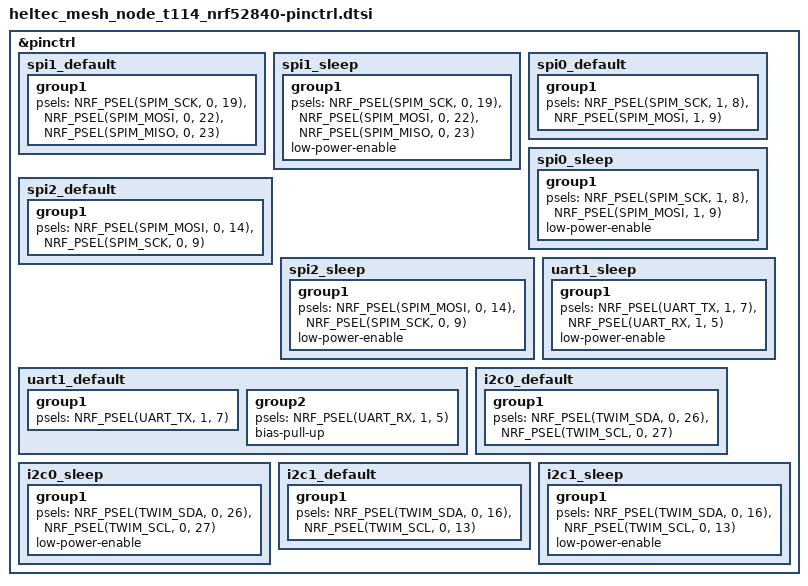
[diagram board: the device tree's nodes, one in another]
/*
 * Copyright (c) 2026 Bruce Fitzsimons
 * SPDX-License-Identifier: Apache-2.0
 *
 * Pin assignments verified against:
 *   - Heltec MeshNode T114 V2.1 schematic
 *     (https://resource.heltec.cn/download/Mesh_Node_T114/schematic/MeshNode-T114_V2.1.pdf)
 *   - Meshtastic firmware variant.h
 *     (variants/nrf52840/heltec_mesh_node_t114/variant.h)
 *
 * SPI bus assignment (Zephyr instance numbering, distinct from Arduino's):
 *   spi0 -> ST7789V TFT display
 *   spi1 -> SX1262 LoRa radio
 *   spi2 -> WS2812 / SK6812 NeoPixel (dummy SCK)
 */

&pinctrl {
	/* SX1262 LoRa radio */
	spi1_default: spi1_default {
		group1 {
			psels = <NRF_PSEL(SPIM_SCK, 0, 19)>,
				<NRF_PSEL(SPIM_MOSI, 0, 22)>,
				<NRF_PSEL(SPIM_MISO, 0, 23)>;
		};
	};

	spi1_sleep: spi1_sleep {
		group1 {
			psels = <NRF_PSEL(SPIM_SCK, 0, 19)>,
				<NRF_PSEL(SPIM_MOSI, 0, 22)>,
				<NRF_PSEL(SPIM_MISO, 0, 23)>;
			low-power-enable;
		};
	};

	/* ST7789V display — write-only, no MISO line */
	spi0_default: spi0_default {
		group1 {
			psels = <NRF_PSEL(SPIM_SCK, 1, 8)>,
				<NRF_PSEL(SPIM_MOSI, 1, 9)>;
		};
	};

	spi0_sleep: spi0_sleep {
		group1 {
			psels = <NRF_PSEL(SPIM_SCK, 1, 8)>,
				<NRF_PSEL(SPIM_MOSI, 1, 9)>;
			low-power-enable;
		};
	};

	/*
	 * NeoPixel chain (2x SK6812). The nRF SPIM peripheral mandates an
	 * SCK pin even though WS2812-via-SPI ignores it; routing SCK to the
	 * unpopulated UART2 RX pad (P0.09) keeps it off any external pin.
	 */
	spi2_default: spi2_default {
		group1 {
			psels = <NRF_PSEL(SPIM_MOSI, 0, 14)>,
				<NRF_PSEL(SPIM_SCK, 0, 9)>;
		};
	};

	spi2_sleep: spi2_sleep {
		group1 {
			psels = <NRF_PSEL(SPIM_MOSI, 0, 14)>,
				<NRF_PSEL(SPIM_SCK, 0, 9)>;
			low-power-enable;
		};
	};

	/*
	 * UART1 — L76K GNSS module (optional, populated on T114 V2 only when
	 * GPS variant is ordered). TX from MCU = P1.07, RX into MCU = P1.05.
	 */
	uart1_default: uart1_default {
		group1 {
			psels = <NRF_PSEL(UART_TX, 1, 7)>;
		};
		group2 {
			psels = <NRF_PSEL(UART_RX, 1, 5)>;
			bias-pull-up;
		};
	};

	uart1_sleep: uart1_sleep {
		group1 {
			psels = <NRF_PSEL(UART_TX, 1, 7)>,
				<NRF_PSEL(UART_RX, 1, 5)>;
			low-power-enable;
		};
	};

	/* I2C0 — RTC footprint (PCF8563TS), unpopulated on V2 */
	i2c0_default: i2c0_default {
		group1 {
			psels = <NRF_PSEL(TWIM_SDA, 0, 26)>,
				<NRF_PSEL(TWIM_SCL, 0, 27)>;
		};
	};

	i2c0_sleep: i2c0_sleep {
		group1 {
			psels = <NRF_PSEL(TWIM_SDA, 0, 26)>,
				<NRF_PSEL(TWIM_SCL, 0, 27)>;
			low-power-enable;
		};
	};

	/* I2C1 — header pins, for user expansion */
	i2c1_default: i2c1_default {
		group1 {
			psels = <NRF_PSEL(TWIM_SDA, 0, 16)>,
				<NRF_PSEL(TWIM_SCL, 0, 13)>;
		};
	};

	i2c1_sleep: i2c1_sleep {
		group1 {
			psels = <NRF_PSEL(TWIM_SDA, 0, 16)>,
				<NRF_PSEL(TWIM_SCL, 0, 13)>;
			low-power-enable;
		};
	};
};
